AUTOSAR XML (schema 4-0-3)
package /ComponentTypes
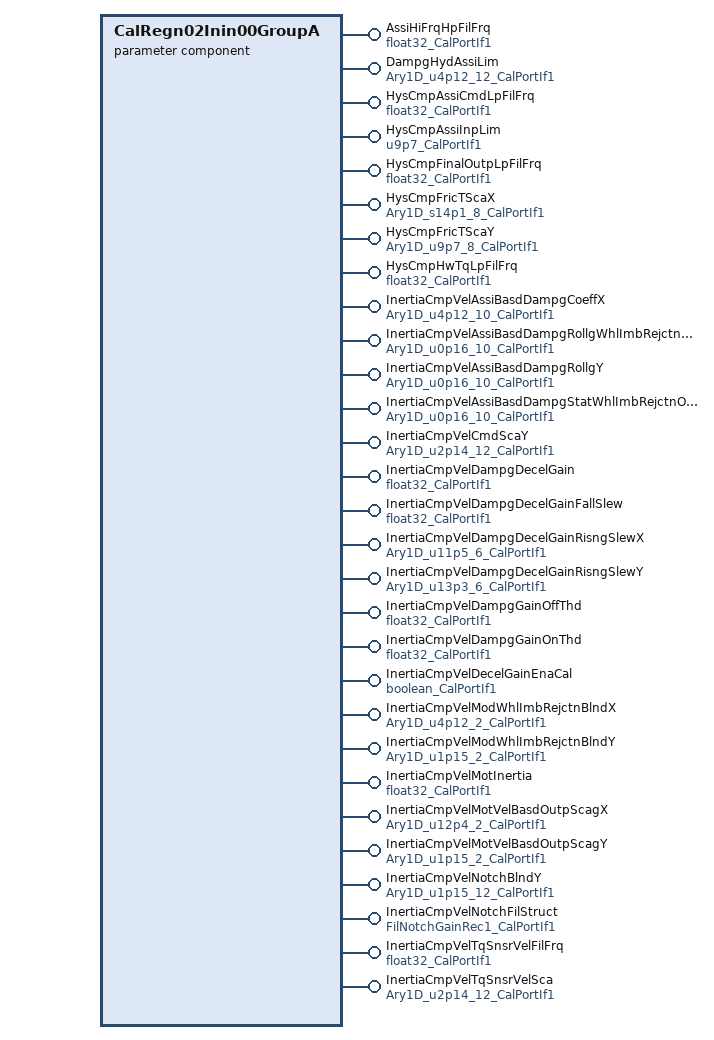
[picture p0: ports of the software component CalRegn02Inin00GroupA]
  parameter sw component type CalRegn02Inin00GroupA
    29 x provide port:
      AssiHiFrqHpFilFrq: parameter-provide-com-spec{init-value=15, parameter=Val}, provided-interface=float32_CalPortIf1
      DampgHydAssiLim: parameter-provide-com-spec{init-value=12 x 36045, parameter=Ary1D}, provided-interface=Ary1D_u4p12_12_CalPortIf1
      HysCmpAssiCmdLpFilFrq: parameter-provide-com-spec{init-value=50, parameter=Val}, provided-interface=float32_CalPortIf1
      HysCmpAssiInpLim: parameter-provide-com-spec{init-value=45056, parameter=Val}, provided-interface=u9p7_CalPortIf1
      HysCmpFinalOutpLpFilFrq: parameter-provide-com-spec{init-value=50, parameter=Val}, provided-interface=float32_CalPortIf1
      HysCmpFricTScaX: parameter-provide-com-spec{init-value=[-80, -60, -40, -20, 0, 50, 100, 160], parameter=Ary1D}, provided-interface=Ary1D_s14p1_8_CalPortIf1
      HysCmpFricTScaY: parameter-provide-com-spec{init-value=8 x 128, parameter=Ary1D}, provided-interface=Ary1D_u9p7_8_CalPortIf1
      HysCmpHwTqLpFilFrq: parameter-provide-com-spec{init-value=50, parameter=Val}, provided-interface=float32_CalPortIf1
      InertiaCmpVelAssiBasdDampgCoeffX: parameter-provide-com-spec{init-value=[0, 2048, 4096, 6144, 8192, 10240, 12288, 14336, 16384, 18432], parameter=Ary1D}, provided-interface=Ary1D_u4p12_10_CalPortIf1
      InertiaCmpVelAssiBasdDampgRollgWhlImbRejctnOnY: parameter-provide-com-spec{init-value=10 x 0, parameter=Ary1D}, provided-interface=Ary1D_u0p16_10_CalPortIf1
      InertiaCmpVelAssiBasdDampgRollgY: parameter-provide-com-spec{init-value=10 x 0, parameter=Ary1D}, provided-interface=Ary1D_u0p16_10_CalPortIf1
      InertiaCmpVelAssiBasdDampgStatWhlImbRejctnOnY: parameter-provide-com-spec{init-value=10 x 0, parameter=Ary1D}, provided-interface=Ary1D_u0p16_10_CalPortIf1
      InertiaCmpVelCmdScaY: parameter-provide-com-spec{init-value=12 x 384, parameter=Ary1D}, provided-interface=Ary1D_u2p14_12_CalPortIf1
      InertiaCmpVelDampgDecelGain: parameter-provide-com-spec{init-value=1, parameter=Val}, provided-interface=float32_CalPortIf1
      InertiaCmpVelDampgDecelGainFallSlew: parameter-provide-com-spec{init-value=-4500, parameter=Val}, provided-interface=float32_CalPortIf1
      InertiaCmpVelDampgDecelGainRisngSlewX: parameter-provide-com-spec{init-value=[0, 640, 1088, 1120, 1152, 1184], parameter=Ary1D}, provided-interface=Ary1D_u11p5_6_CalPortIf1
      InertiaCmpVelDampgDecelGainRisngSlewY: parameter-provide-com-spec{init-value=6 x 36000, parameter=Ary1D}, provided-interface=Ary1D_u13p3_6_CalPortIf1
      InertiaCmpVelDampgGainOffThd: parameter-provide-com-spec{init-value=1, parameter=Val}, provided-interface=float32_CalPortIf1
      InertiaCmpVelDampgGainOnThd: parameter-provide-com-spec{init-value=10, parameter=Val}, provided-interface=float32_CalPortIf1
      InertiaCmpVelDecelGainEnaCal: parameter-provide-com-spec{init-value=0, parameter=Logl}, provided-interface=boolean_CalPortIf1
      InertiaCmpVelModWhlImbRejctnBlndX: parameter-provide-com-spec{init-value=[0, 4096], parameter=Ary1D}, provided-interface=Ary1D_u4p12_2_CalPortIf1
      InertiaCmpVelModWhlImbRejctnBlndY: parameter-provide-com-spec{init-value=[32768, 0], parameter=Ary1D}, provided-interface=Ary1D_u1p15_2_CalPortIf1
      InertiaCmpVelMotInertia: parameter-provide-com-spec{init-value=0.001, parameter=Val}, provided-interface=float32_CalPortIf1
      InertiaCmpVelMotVelBasdOutpScagX: parameter-provide-com-spec{init-value=[1005, 1100], parameter=Ary1D}, provided-interface=Ary1D_u12p4_2_CalPortIf1
      InertiaCmpVelMotVelBasdOutpScagY: parameter-provide-com-spec{init-value=[32768, 32768], parameter=Ary1D}, provided-interface=Ary1D_u1p15_2_CalPortIf1
      InertiaCmpVelNotchBlndY: parameter-provide-com-spec{init-value=12 x 0, parameter=Ary1D}, provided-interface=Ary1D_u1p15_12_CalPortIf1
      InertiaCmpVelNotchFilStruct: parameter-provide-com-spec=Rec, provided-interface=FilNotchGainRec1_CalPortIf1
      InertiaCmpVelTqSnsrVelFilFrq: parameter-provide-com-spec{init-value=20, parameter=Val}, provided-interface=float32_CalPortIf1
      InertiaCmpVelTqSnsrVelSca: parameter-provide-com-spec{init-value=12 x 0, parameter=Ary1D}, provided-interface=Ary1D_u2p14_12_CalPortIf1
